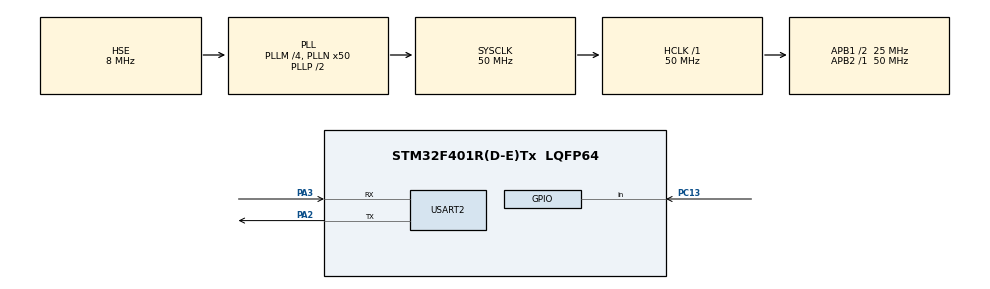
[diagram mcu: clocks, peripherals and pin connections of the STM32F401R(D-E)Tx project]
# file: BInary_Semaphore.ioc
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FREERTOS.BinarySemaphores01=myBinarySem01,Dynamic,NULL,Available
FREERTOS.Tasks01=NormalTask,0,128,StartNormalTask,Default,NULL,Dynamic,NULL,NULL;HIghTask,1,128,StartHIghTask,Default,NULL,Dynamic,NULL,NULL;LowTask,-1,128,StartLowTask,Default,NULL,Dynamic,NULL,NULL
Mcu.Family=STM32F4
Mcu.Name=STM32F401R(D-E)Tx
Mcu.Package=LQFP64
NVIC.PriorityGroup=NVIC_PRIORITYGROUP_4
NVIC.TIM1_UP_TIM10_IRQn=true\:15\:0\:false\:false\:true\:false\:false\:true\:true
NVIC.TimeBase=TIM1_UP_TIM10_IRQn
NVIC.TimeBaseIP=TIM1
PA2.Mode=Asynchronous
PA2.Signal=USART2_TX
PA3.Mode=Asynchronous
PA3.Signal=USART2_RX
PC13-ANTI_TAMP.Signal=GPIO_Input
PH0\ -\ OSC_IN.Mode=HSE-External-Oscillator
PH0\ -\ OSC_IN.Signal=RCC_OSC_IN
PH1\ -\ OSC_OUT.Mode=HSE-External-Oscillator
PH1\ -\ OSC_OUT.Signal=RCC_OSC_OUT
ProjectManager.HeapSize=0x200
ProjectManager.StackSize=0x400
ProjectManager.TargetToolchain=STM32CubeIDE
RCC.48MHZClocksFreq_Value=25000000
RCC.AHBFreq_Value=50000000
RCC.APB1CLKDivider=RCC_HCLK_DIV2
RCC.APB1Freq_Value=25000000
RCC.APB1TimCLKDivider=2
RCC.APB1TimFreq_Value=50000000
RCC.APB2Freq_Value=50000000
RCC.APB2TimFreq_Value=50000000
RCC.CortexFreq_Value=50000000
RCC.HCLKFreq_Value=50000000
RCC.HSE_VALUE=8000000
RCC.HSI_VALUE=16000000
RCC.LSE_VALUE=32768
RCC.PLLM=4
RCC.PLLN=50
RCC.PLLSourceVirtual=RCC_PLLSOURCE_HSE
RCC.SYSCLKFreq_VALUE=50000000
RCC.SYSCLKSource=RCC_SYSCLKSOURCE_PLLCLK
RCC.VCOOutputFreq_Value=100000000
USART2.VirtualMode=VM_ASYNC
VP_FREERTOS_VS_CMSIS_V1.Mode=CMSIS_V1
VP_SYS_VS_tim1.Mode=TIM1
board=custom

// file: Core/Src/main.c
/* USER CODE BEGIN Header */
/**
  ******************************************************************************
  * @file           : main.c
  * @brief          : Main program body
  ******************************************************************************
  * @attention
  *
  * Copyright (c) 2025 STMicroelectronics.
  * All rights reserved.
  *
  * This software is licensed under terms that can be found in the LICENSE file
  * in the root directory of this software component.
  * If no LICENSE file comes with this software, it is provided AS-IS.
  *
  ******************************************************************************
  */
/* USER CODE END Header */
#include "main.h"
#include "cmsis_os.h"
#include "string.h"

UART_HandleTypeDef huart2;

osThreadId NormalTaskHandle;
osThreadId HIghTaskHandle;
osThreadId LowTaskHandle;
osSemaphoreId myBinarySem01Handle;

void SystemClock_Config(void);
static void MX_GPIO_Init(void);
static void MX_USART2_UART_Init(void);
void StartNormalTask(void const * argument);
void StartHIghTask(void const * argument);
void StartLowTask(void const * argument);

int main(void)
{

  /* MCU Configuration--------------------------------------------------------*/

  /* Reset of all peripherals, Initializes the Flash interface and the Systick. */
  HAL_Init();

  /* Configure the system clock */
  SystemClock_Config();

  /* Initialize all configured peripherals */
  MX_GPIO_Init();
  MX_USART2_UART_Init();

  /* Create the semaphores(s) */
  /* definition and creation of myBinarySem01 */
  osSemaphoreDef(myBinarySem01);
  myBinarySem01Handle = osSemaphoreCreate(osSemaphore(myBinarySem01), 1);

  /* Create the thread(s) */
  /* definition and creation of NormalTask */
  osThreadDef(NormalTask, StartNormalTask, osPriorityNormal, 0, 128);
  NormalTaskHandle = osThreadCreate(osThread(NormalTask), NULL);

  /* definition and creation of HIghTask */
  osThreadDef(HIghTask, StartHIghTask, osPriorityAboveNormal, 0, 128);
  HIghTaskHandle = osThreadCreate(osThread(HIghTask), NULL);

  /* definition and creation of LowTask */
  osThreadDef(LowTask, StartLowTask, osPriorityBelowNormal, 0, 128);
  LowTaskHandle = osThreadCreate(osThread(LowTask), NULL);

  /* Start scheduler */
  osKernelStart();

  /* We should never get here as control is now taken by the scheduler */

  /* Infinite loop */
  while (1)
  {

  }
}

void SystemClock_Config(void)
{
  RCC_OscInitTypeDef RCC_OscInitStruct = {0};
  RCC_ClkInitTypeDef RCC_ClkInitStruct = {0};

  /** Configure the main internal regulator output voltage
  */
  __HAL_RCC_PWR_CLK_ENABLE();
  __HAL_PWR_VOLTAGESCALING_CONFIG(PWR_REGULATOR_VOLTAGE_SCALE2);

  /** Initializes the RCC Oscillators according to the specified parameters
  * in the RCC_OscInitTypeDef structure.
  */
  RCC_OscInitStruct.OscillatorType = RCC_OSCILLATORTYPE_HSE;
  RCC_OscInitStruct.HSEState = RCC_HSE_ON;
  RCC_OscInitStruct.PLL.PLLState = RCC_PLL_ON;
  RCC_OscInitStruct.PLL.PLLSource = RCC_PLLSOURCE_HSE;
  RCC_OscInitStruct.PLL.PLLM = 4;
  RCC_OscInitStruct.PLL.PLLN = 50;
  RCC_OscInitStruct.PLL.PLLP = RCC_PLLP_DIV2;
  RCC_OscInitStruct.PLL.PLLQ = 4;
  if (HAL_RCC_OscConfig(&RCC_OscInitStruct) != HAL_OK)
  {
    Error_Handler();
  }

  /** Initializes the CPU, AHB and APB buses clocks
  */
  RCC_ClkInitStruct.ClockType = RCC_CLOCKTYPE_HCLK|RCC_CLOCKTYPE_SYSCLK
                              |RCC_CLOCKTYPE_PCLK1|RCC_CLOCKTYPE_PCLK2;
  RCC_ClkInitStruct.SYSCLKSource = RCC_SYSCLKSOURCE_PLLCLK;
  RCC_ClkInitStruct.AHBCLKDivider = RCC_SYSCLK_DIV1;
  RCC_ClkInitStruct.APB1CLKDivider = RCC_HCLK_DIV2;
  RCC_ClkInitStruct.APB2CLKDivider = RCC_HCLK_DIV1;

  if (HAL_RCC_ClockConfig(&RCC_ClkInitStruct, FLASH_LATENCY_1) != HAL_OK)
  {
    Error_Handler();
  }
}

static void MX_USART2_UART_Init(void)
{

  huart2.Instance = USART2;
  huart2.Init.BaudRate = 115200;
  huart2.Init.WordLength = UART_WORDLENGTH_8B;
  huart2.Init.StopBits = UART_STOPBITS_1;
  huart2.Init.Parity = UART_PARITY_NONE;
  huart2.Init.Mode = UART_MODE_TX_RX;
  huart2.Init.HwFlowCtl = UART_HWCONTROL_NONE;
  huart2.Init.OverSampling = UART_OVERSAMPLING_16;
  if (HAL_UART_Init(&huart2) != HAL_OK)
  {
    Error_Handler();
  }

}

static void MX_GPIO_Init(void)
{
  GPIO_InitTypeDef GPIO_InitStruct = {0};

  /* GPIO Ports Clock Enable */
  __HAL_RCC_GPIOC_CLK_ENABLE();
  __HAL_RCC_GPIOH_CLK_ENABLE();
  __HAL_RCC_GPIOA_CLK_ENABLE();

  /*Configure GPIO pin : PC13 */
  GPIO_InitStruct.Pin = GPIO_PIN_13;
  GPIO_InitStruct.Mode = GPIO_MODE_INPUT;
  GPIO_InitStruct.Pull = GPIO_NOPULL;
  HAL_GPIO_Init(GPIOC, &GPIO_InitStruct);

}

void StartNormalTask(void const * argument)
{
  /* USER CODE BEGIN 5 */
  /* Infinite loop */
  for(;;)
  {
	char *str1 = "Entered NormalTask and waiting for semaphore\n";
	HAL_UART_Transmit(&huart2, (uint8_t *)str1, strlen(str1), 100);

	osSemaphoreWait(myBinarySem01Handle, osWaitForever);

	char *str3 = "Semaphore acquired by normal task\n";
	HAL_UART_Transmit(&huart2, (uint8_t *)str3, strlen(str3), 100);

	while(HAL_GPIO_ReadPin(GPIOC, GPIO_PIN_13)); // wait till the pin goes low

	char *str2 = "Leaving NormalTask and releasing the semaphore\n";
	HAL_UART_Transmit(&huart2, (uint8_t *)str2, strlen(str2), 100);

	osSemaphoreRelease(myBinarySem01Handle);
	osDelay(500);
  }
  /* USER CODE END 5 */
}

void StartHIghTask(void const * argument)
{
  /* USER CODE BEGIN StartHIghTask */
  /* Infinite loop */
  for(;;)
  {
		char *str1 = "Entered HighTask and waiting for semaphore\n";
		HAL_UART_Transmit(&huart2, (uint8_t *)str1, strlen(str1), 100);

		osSemaphoreWait(myBinarySem01Handle, osWaitForever);

		char *str3 = "Semaphore acquired by high task\n";
		HAL_UART_Transmit(&huart2, (uint8_t *)str3, strlen(str3), 100);

		char *str2 = "Leaving HighTask and releasing the semaphore\n";
		HAL_UART_Transmit(&huart2, (uint8_t *)str2, strlen(str2), 100);

		osSemaphoreRelease(myBinarySem01Handle);
		osDelay(500);
  }
  /* USER CODE END StartHIghTask */
}

void StartLowTask(void const * argument)
{
  /* USER CODE BEGIN StartLowTask */
  /* Infinite loop */
  for(;;)
  {
	char *str1 = "Entered LowTask\n";
	HAL_UART_Transmit(&huart2, (uint8_t *)str1, strlen(str1), 100);

	char *str2 = "Leaving LowTask\n";
	HAL_UART_Transmit(&huart2, (uint8_t *)str2, strlen(str2), 100);
	osDelay(500);
  }
  /* USER CODE END StartLowTask */
}

void HAL_TIM_PeriodElapsedCallback(TIM_HandleTypeDef *htim)
{
  if (htim->Instance == TIM1)
  {
    HAL_IncTick();
  }
}

void Error_Handler(void)
{
  __disable_irq();
  while (1)
  {
  }
}
